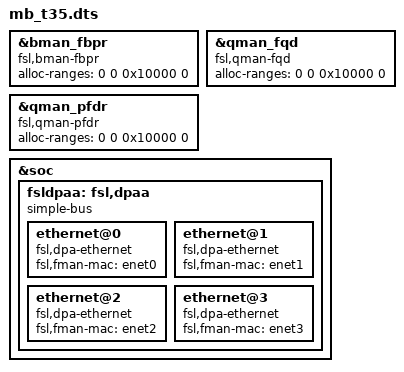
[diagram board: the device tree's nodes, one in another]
/include/ "mb_t35-pre.dts"

/include/ "qoriq-fman3-0-sdk.dtsi"
/include/ "qoriq-bman-portals-sdk.dtsi"
/include/ "qoriq-qman3-portals-sdk.dtsi"
/include/ "qoriq-qman3-ceetm0-8-sdk.dtsi"

&bman_fbpr {
	compatible = "fsl,bman-fbpr";
	alloc-ranges = <0 0 0x10000 0>;
};

&qman_fqd {
	compatible = "fsl,qman-fqd";
	alloc-ranges = <0 0 0x10000 0>;
};

&qman_pfdr {
	compatible = "fsl,qman-pfdr";
	alloc-ranges = <0 0 0x10000 0>;
};

&soc {
	fsldpaa: fsl,dpaa {
		compatible = "simple-bus", "fsl,dpaa";
		ethernet@0 {
			compatible = "fsl,dpa-ethernet";
			fsl,fman-mac = <&enet0>;
		};
		ethernet@1 {
			compatible = "fsl,dpa-ethernet";
			fsl,fman-mac = <&enet1>;
		};
		ethernet@2 {
			compatible = "fsl,dpa-ethernet";
			fsl,fman-mac = <&enet2>;
		};
		ethernet@3 {
			compatible = "fsl,dpa-ethernet";
			fsl,fman-mac = <&enet3>;
		};
	};
};
